# ADuCM350 register map
Vendor: Analog Devices; Series: ARMCM3; File version: 0.1
Cortex-M3 Microcontroller Device, CPU clock up to 16MHz, etc.
CPU: CM3 r2p1, little endian, no MPU, no FPU, 3 interrupt priority bits
Registers are 16-bit, access not given, no defined reset value unless marked. A register's access mark holds for its fields unless they carry their own. Offsets are from the block's base; lines under a group give offsets from that group; [hi:lo] are bit positions; {n}, {i} and the like mark numbered series; 'fields as' and 'values as' point back to an identical list; <NAME> marks a mode.

## Memory map
0x40000000 GPT0 size 0x28 — General Purpose Timer 0
0x40000400 GPT1 size 0x28 — General Purpose Timer1
0x40000800 GPT2 size 0x28 — General Purpose Timer2
0x40002400 PWR size 0x90 — Power Management Unit
0x40002500 WUT size 0x44 — Wake-up timer
0x40002580 WDT size 0x1C — WatchDog Timer
0x40002600 RTC size 0x24 — RealTimeClock
0x40003000 I2C size 0x58 — I2C Master/Slave
0x40004000 SPI0 size 0x1C — SPI0 Maste/Slave
0x40004400 SPI1 size 0x1C — SPI1 Master/Slave
0x40005000 UART size 0x34
0x40005800 I2S size 0x24 — I2S Master/Slave
0x40005C00 BEEP size 0x10 — Beeper
0x40006000 RNG size 0x18 — Random Bit Generator
0x40008000 LCD size 0x50 — LCD Controller
0x40010000 DMA size 0x1000
0x40018000 FEE0 size 0x88 — Instruction Flash Controller
0x4001C000 GPF size 0x86 — General Purpose Flash Controller
0x40020000 GPIO0 size 0xB8 — GPIO
0x40024000 SPIH size 0x1C — SPIH Master/Slave
0x4002C000 CRC size 0x100 — CRC Engine
0x40030000 PDI size 0x4C — Parallel Display Interface
0x40080000 AFE size 0x148 — Analog Front End
0x400A0000 USB0 size 0x3B8 — USB Controller

## Interrupts
0 WUT — Wake Up Timer interrupt
10 WDT — interrupt
11 TIMER0 (GPT0)
12 TIMER1 (GPT1)
14 Uart (UART) — interrupt
15 SPI0 — SPI 0 interrupt
16 SPIH — interrupt
17 I2C0 (I2C) — I2C 0 interrupt
19 DMA — DMA interrupt
37 USB (USB0) — USB Controller interrupt
39 I2S — I2S interrupt
42 SPI1 — interrupt
43 RTC — Real Time Clock interrupt
45 Beep (BEEP) — Beep interrupt
46 LCD — LCD Controller interrupt
47 GPIOA (GPIO0) — interrupt
50 AFE — Analog Front End interrupt
55 Flash_EEprom (FEE0) — Flash EEPROM interrupt
58 RBG (RNG) — Random Bit Generator interrupt
59 PDI — Paraller Display Interface interrupt

## GPT0 — General Purpose Timer 0
Base 0x40000000
0x00 REG_GPT0_GPTLD — 16-bit load value
  [15:0] VALUE — Load value
0x04 REG_GPT0_GPTVAL — 16-bit timer value. read only.
  [15:0] VALUE — Current value
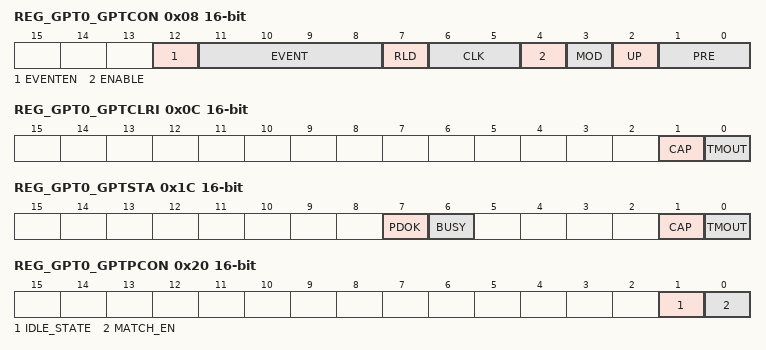
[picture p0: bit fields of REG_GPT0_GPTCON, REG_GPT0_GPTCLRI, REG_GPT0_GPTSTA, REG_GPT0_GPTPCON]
0x08 REG_GPT0_GPTCON — Control Register
  [12] EVENTEN — Enable time capture of an event
    0=DIS; 1=EN
  [11:8] EVENT — Event Select, selects 1 of the available events.
    0=T2 (- Wakeup Timer); {v}=EXT{v-1} (- External interrupt {v-1}) (v=1..8); 9=T3 (- Watchdog timer); 10=T1 (- Timer1); 11=ADC0; 12=ADC1; 13=STEP; 14=DMADONE; 15=FEE (- Flash controller)
  [7] RLD — Timer reload on write to clear register
    0=DIS; 1=EN
  [6:5] CLK — Clock Select
    0=UCLK (- System Clock); 1=PCLK (- Peripheral clock); 2=LFOSC (- Internal 32 kHz Oscillator); 3=LFXTAL (- External 32 kHz crystal)
  [4] ENABLE
    0=DIS; 1=EN
  [3] MOD — Mode
    0=FREERUN; 1=PERIODIC
  [2] UP — Count-up
    0=DIS; 1=EN
  [1:0] PRE — Prescaler
    0=DIV1; 1=DIV16; 2=DIV256; 3=DIV32768 (- If the selected clock source is UCLK then this setting results in a prescaler of 4.)
0x0C REG_GPT0_GPTCLRI — Clear interrupt register
  [1] CAP — Clear captured event interrupt
    1=CLR
  [0] TMOUT — Clear timeout interrupt
    1=CLR
0x10 REG_GPT0_GPTCAP — Capture Register
  [15:0] VALUE — Capture value
0x14 REG_GPT0_GPTALD — 16-bit load value, asynchronous
  [15:0] ALOAD — Load value
0x18 REG_GPT0_GPTAVAL — 16-bit timer value, asynchronous
  [15:0] AVALUE — Value
0x1C REG_GPT0_GPTSTA — Status
  [7] PDOK — GPTI Sync
  [6] BUSY — Timer Busy
  [1] CAP — Capture event pending
  [0] TMOUT — Time out event occured
0x20 REG_GPT0_GPTPCON — PWM Control Register
  [1] IDLE_STATE — Idle Hi/Lo
  [0] MATCH_EN — High or Toggle
0x24 REG_GPT0_GPTPMAT — PWM Match Value
  [15:0] MATCH_VAL — PWM Match value

## GPT1 — General Purpose Timer1
Base 0x40000400
Registers as GPT0 (with GPT0 read as GPT1); these are added or differ:
0x04 REG_GPT1_GPTVAL — 16-bit timer value
  [15:0] VALUE — Current value
0x10 REG_GPT1_GPTCAP — Capture
  [15:0] VALUE — Capture value
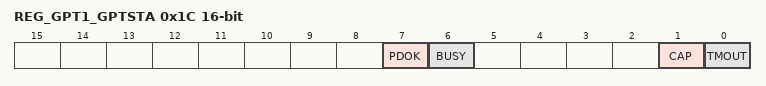
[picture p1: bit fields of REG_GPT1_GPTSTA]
0x1C REG_GPT1_GPTSTA — Status Register
  [7] PDOK — GPTI Sync
  [6] BUSY — Timer Busy
  [1] CAP — Capture event pending
  [0] TMOUT — Timer timeout
